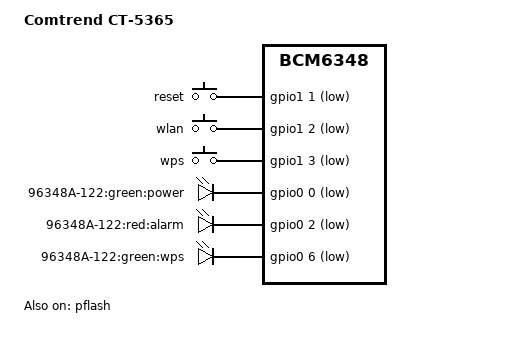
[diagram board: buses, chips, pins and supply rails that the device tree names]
/dts-v1/;

/include/ "bcm6348.dtsi"

/ {
	model = "Comtrend CT-5365";
	compatible = "comtrend,ct-5365", "brcm,bcm6348";

	gpio-keys-polled {
		compatible = "gpio-keys-polled";
		#address-cells = <1>;
		#size-cells = <0>;
		poll-interval = <20>;
		debounce-interval = <60>;

		reset {
			label = "reset";
			gpios = <&gpio1 1 1>;
			linux,code = <0x198>;
		};
		wlan {
			label = "wlan";
			gpios = <&gpio1 2 1>;
			linux,code = <0xee>;
		};
		wps {
			label = "wps";
			gpios = <&gpio1 3 1>;
			linux,code = <0x211>;
		};
	};

	gpio-leds {
		compatible = "gpio-leds";

		power_green {
			label = "96348A-122:green:power";
			gpios = <&gpio0 0 1>;
			default-state = "on";
		};
		alarm_red {
			label = "96348A-122:red:alarm";
			gpios = <&gpio0 2 1>;
		};
		wps_green {
			label = "96348A-122:green:wps";
			gpios = <&gpio0 6 1>;
		};
	};
};

&pflash {
	status = "ok";

	linux,part-probe = "bcm63xxpart";

	cfe@0 {
		label = "CFE";
		reg = <0x000000 0x010000>;
		read-only;
	};

	linux@10000 {
		label = "linux";
		reg = <0x010000 0x3e0000>;
	};

	nvram@3f0000 {
		label = "nvram";
		reg = <0x3f0000 0x010000>;
	};
};
